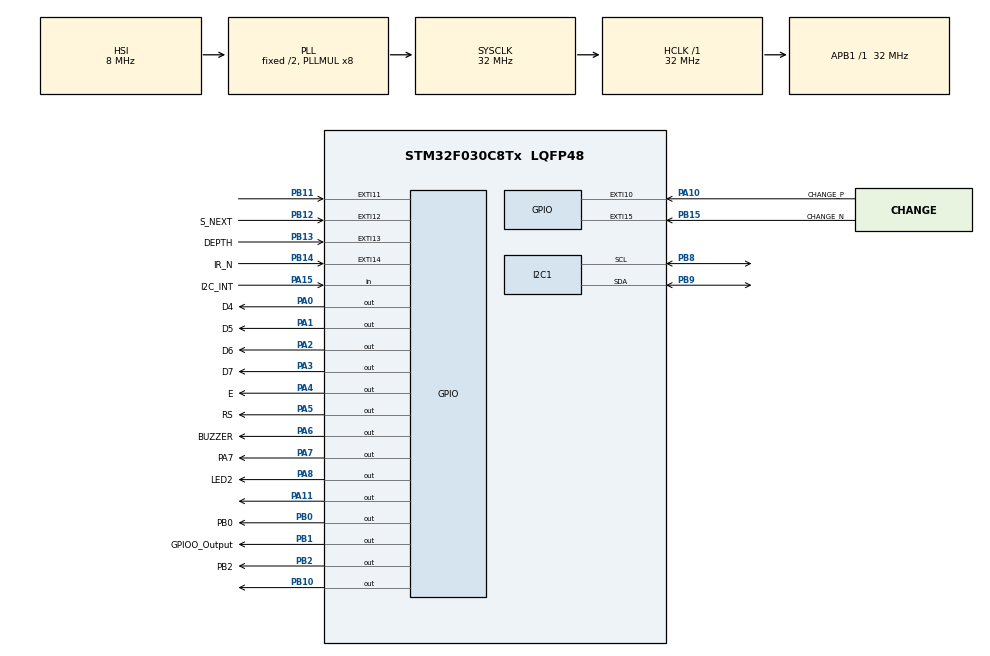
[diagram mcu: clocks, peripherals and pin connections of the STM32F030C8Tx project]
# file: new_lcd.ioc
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Mcu.Family=STM32F0
Mcu.Name=STM32F030C8Tx
Mcu.Package=LQFP48
PA0.GPIO_Label=D4
PA0.Signal=GPIO_Output
PA1.GPIO_Label=D5
PA1.Signal=GPIO_Output
PA10.GPIO_Label=CHANGE_P
PA10.Signal=GPXTI10
PA11.Signal=GPIO_Output
PA12.Signal=USART1_DE
PA13.Mode=Serial_Wire
PA13.Signal=SYS_SWDIO
PA14.Mode=Serial_Wire
PA14.Signal=SYS_SWCLK
PA15.GPIO_Label=I2C_INT
PA15.Signal=GPIO_Input
PA2.GPIO_Label=D6
PA2.Signal=GPIO_Output
PA3.GPIO_Label=D7
PA3.Signal=GPIO_Output
PA4.GPIO_Label=E
PA4.Signal=GPIO_Output
PA5.GPIO_Label=RS
PA5.Signal=GPIO_Output
PA6.GPIO_Label=BUZZER
PA6.Signal=GPIO_Output
PA7.GPIO_Label=PA7
PA7.Signal=GPIO_Output
PA8.GPIO_Label=LED2
PA8.Signal=GPIO_Output
PB0.GPIO_Label=PB0
PB0.Signal=GPIO_Output
PB1.GPIO_Label=GPIOO_Output
PB1.Signal=GPIO_Output
PB10.Signal=GPIO_Output
PB11.Signal=GPXTI11
PB12.GPIO_Label=S_NEXT
PB12.Signal=GPXTI12
PB13.GPIO_Label=DEPTH
PB13.Signal=GPXTI13
PB14.GPIO_Label=IR_N
PB14.Signal=GPXTI14
PB15.GPIO_Label=CHANGE_N
PB15.Signal=GPXTI15
PB2.GPIO_Label=PB2
PB2.Signal=GPIO_Output
PB6.Signal=USART1_TX
PB7.Signal=USART1_RX
PB8.Mode=I2C
PB8.Signal=I2C1_SCL
PB9.Mode=I2C
PB9.Signal=I2C1_SDA
PF0-OSC_IN.Mode=HSE-External-Oscillator
PF0-OSC_IN.Signal=RCC_OSC_IN
PF1-OSC_OUT.Mode=HSE-External-Oscillator
PF1-OSC_OUT.Signal=RCC_OSC_OUT
ProjectManager.HeapSize=0x200
ProjectManager.StackSize=0x400
ProjectManager.TargetToolchain=STM32CubeIDE
RCC.AHBFreq_Value=32000000
RCC.APB1Freq_Value=32000000
RCC.APB1TimFreq_Value=32000000
RCC.HCLKFreq_Value=32000000
RCC.PLLMUL=RCC_PLL_MUL8
RCC.SYSCLKFreq_VALUE=32000000
RCC.SYSCLKSource=RCC_SYSCLKSOURCE_PLLCLK
VP_TIM6_VS_ClockSourceINT.Mode=Enable_Timer
board=custom

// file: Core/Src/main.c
/* USER CODE BEGIN Header */
/**
  ******************************************************************************
  * @file           : main.c
  * @brief          : Main program body
  ******************************************************************************
  * @attention
  *
  * Copyright (c) 2023 STMicroelectronics.
  * All rights reserved.
  *
  * This software is licensed under terms that can be found in the LICENSE file
  * in the root directory of this software component.
  * If no LICENSE file comes with this software, it is provided AS-IS.
  *
  ******************************************************************************
  */
/* USER CODE END Header */
#include "main.h"

/* USER CODE BEGIN PTD */
//PIN_HIGH(D4_PORT, D4_PIN);
/* USER CODE END PTD */

I2C_HandleTypeDef hi2c1;

TIM_HandleTypeDef htim6;

void SystemClock_Config(void);
static void MX_GPIO_Init(void);
static void MX_I2C1_Init(void);
static void MX_TIM6_Init(void);

int main(void)
{

  /* MCU Configuration--------------------------------------------------------*/

  /* Reset of all peripherals, Initializes the Flash interface and the Systick. */
  HAL_Init();

  /* Configure the system clock */
  SystemClock_Config();

  /* Initialize all configured peripherals */
  MX_GPIO_Init();
  MX_I2C1_Init();
  MX_TIM6_Init();
  /* USER CODE BEGIN 2 */
#define BUTTON_STATE HAL_GPIO_ReadPin(GPIOB, GPIO_PIN_13)
#define LED_HIGH HAL_GPIO_WritePin(GPIOB, GPIO_PIN_11, GPIO_PIN_RESET)
#define LED_LOW HAL_GPIO_WritePin(GPIOB, GPIO_PIN_11, GPIO_PIN_SET)
  /* USER CODE END 2 */

  /* Infinite loop */
  while (1)
  {
//	    HAL_GPIO_WritePin(GPIOA, GPIO_PIN_13, 0);
//	  	HAL_Delay(1000);
//	  	HAL_GPIO_WritePin(GPIOA, GPIO_PIN_13, 1);
//	  	HAL_Delay(1000);
//		HAL_GPIO_WritePin(GPIOA, GPIO_PIN_13, 1);
//		  	HAL_Delay(1000);
    /* USER CODE BEGIN 3 */
	  if(BUTTON_STATE == 1)
	        {
	            LED_HIGH;
	        }
	      else
	        {
	            LED_LOW;
	        }
//		  	HAL_GPIO_TogglePin(GPIOA,pg2);
//		  		  	HAL_Delay(1000);
//			HAL_GPIO_TogglePin(GPIOA, GPIO_PIN_11);
//				  		  	HAL_Delay(1000);
//		  			HAL_GPIO_WritePin(GPIOA, GPIO_PIN_led1, 0);
//		  			  	HAL_Delay(1000);
  }
  /* USER CODE END 3 */
}

void SystemClock_Config(void)
{
  RCC_OscInitTypeDef RCC_OscInitStruct = {0};
  RCC_ClkInitTypeDef RCC_ClkInitStruct = {0};
  RCC_PeriphCLKInitTypeDef PeriphClkInit = {0};

  /** Initializes the RCC Oscillators according to the specified parameters
  * in the RCC_OscInitTypeDef structure.
  */
  RCC_OscInitStruct.OscillatorType = RCC_OSCILLATORTYPE_HSI;
  RCC_OscInitStruct.HSIState = RCC_HSI_ON;
  RCC_OscInitStruct.HSICalibrationValue = RCC_HSICALIBRATION_DEFAULT;
  RCC_OscInitStruct.PLL.PLLState = RCC_PLL_ON;
  RCC_OscInitStruct.PLL.PLLSource = RCC_PLLSOURCE_HSI;
  RCC_OscInitStruct.PLL.PLLMUL = RCC_PLL_MUL8;
  RCC_OscInitStruct.PLL.PREDIV = RCC_PREDIV_DIV1;
  if (HAL_RCC_OscConfig(&RCC_OscInitStruct) != HAL_OK)
  {
    Error_Handler();
  }

  /** Initializes the CPU, AHB and APB buses clocks
  */
  RCC_ClkInitStruct.ClockType = RCC_CLOCKTYPE_HCLK|RCC_CLOCKTYPE_SYSCLK
                              |RCC_CLOCKTYPE_PCLK1;
  RCC_ClkInitStruct.SYSCLKSource = RCC_SYSCLKSOURCE_PLLCLK;
  RCC_ClkInitStruct.AHBCLKDivider = RCC_SYSCLK_DIV1;
  RCC_ClkInitStruct.APB1CLKDivider = RCC_HCLK_DIV1;

  if (HAL_RCC_ClockConfig(&RCC_ClkInitStruct, FLASH_LATENCY_1) != HAL_OK)
  {
    Error_Handler();
  }
  PeriphClkInit.PeriphClockSelection = RCC_PERIPHCLK_I2C1;
  PeriphClkInit.I2c1ClockSelection = RCC_I2C1CLKSOURCE_HSI;
  if (HAL_RCCEx_PeriphCLKConfig(&PeriphClkInit) != HAL_OK)
  {
    Error_Handler();
  }
}

static void MX_I2C1_Init(void)
{

  hi2c1.Instance = I2C1;
  hi2c1.Init.Timing = 0x2000090E;
  hi2c1.Init.OwnAddress1 = 0;
  hi2c1.Init.AddressingMode = I2C_ADDRESSINGMODE_7BIT;
  hi2c1.Init.DualAddressMode = I2C_DUALADDRESS_DISABLE;
  hi2c1.Init.OwnAddress2 = 0;
  hi2c1.Init.OwnAddress2Masks = I2C_OA2_NOMASK;
  hi2c1.Init.GeneralCallMode = I2C_GENERALCALL_DISABLE;
  hi2c1.Init.NoStretchMode = I2C_NOSTRETCH_DISABLE;
  if (HAL_I2C_Init(&hi2c1) != HAL_OK)
  {
    Error_Handler();
  }

  /** Configure Analogue filter
  */
  if (HAL_I2CEx_ConfigAnalogFilter(&hi2c1, I2C_ANALOGFILTER_ENABLE) != HAL_OK)
  {
    Error_Handler();
  }

  /** Configure Digital filter
  */
  if (HAL_I2CEx_ConfigDigitalFilter(&hi2c1, 0) != HAL_OK)
  {
    Error_Handler();
  }

}

static void MX_TIM6_Init(void)
{

  htim6.Instance = TIM6;
  htim6.Init.Prescaler = 0;
  htim6.Init.CounterMode = TIM_COUNTERMODE_UP;
  htim6.Init.Period = 65535;
  htim6.Init.AutoReloadPreload = TIM_AUTORELOAD_PRELOAD_DISABLE;
  if (HAL_TIM_Base_Init(&htim6) != HAL_OK)
  {
    Error_Handler();
  }

}

static void MX_GPIO_Init(void)
{
  GPIO_InitTypeDef GPIO_InitStruct = {0};

  /* GPIO Ports Clock Enable */
  __HAL_RCC_GPIOF_CLK_ENABLE();
  __HAL_RCC_GPIOA_CLK_ENABLE();
  __HAL_RCC_GPIOB_CLK_ENABLE();

  /*Configure GPIO pin Output Level */
  HAL_GPIO_WritePin(GPIOA, D4_Pin|D5_Pin|D6_Pin|D7_Pin
                          |E_Pin|RS_Pin|BUZZER_Pin|PA7_Pin
                          |LED2_Pin|GPIO_PIN_11, GPIO_PIN_RESET);

  /*Configure GPIO pin Output Level */
  HAL_GPIO_WritePin(GPIOB, PB0_Pin|GPIOO_Output_Pin|PB2_Pin|GPIO_PIN_10, GPIO_PIN_RESET);

  /*Configure GPIO pins : D4_Pin D5_Pin D6_Pin D7_Pin
                           E_Pin RS_Pin BUZZER_Pin PA7_Pin
                           LED2_Pin PA11 */
  GPIO_InitStruct.Pin = D4_Pin|D5_Pin|D6_Pin|D7_Pin
                          |E_Pin|RS_Pin|BUZZER_Pin|PA7_Pin
                          |LED2_Pin|GPIO_PIN_11;
  GPIO_InitStruct.Mode = GPIO_MODE_OUTPUT_PP;
  GPIO_InitStruct.Pull = GPIO_NOPULL;
  GPIO_InitStruct.Speed = GPIO_SPEED_FREQ_LOW;
  HAL_GPIO_Init(GPIOA, &GPIO_InitStruct);

  /*Configure GPIO pins : PB0_Pin GPIOO_Output_Pin PB2_Pin PB10 */
  GPIO_InitStruct.Pin = PB0_Pin|GPIOO_Output_Pin|PB2_Pin|GPIO_PIN_10;
  GPIO_InitStruct.Mode = GPIO_MODE_OUTPUT_PP;
  GPIO_InitStruct.Pull = GPIO_NOPULL;
  GPIO_InitStruct.Speed = GPIO_SPEED_FREQ_LOW;
  HAL_GPIO_Init(GPIOB, &GPIO_InitStruct);

  /*Configure GPIO pins : PB11 S_NEXT_Pin DEPTH_Pin IR_N_Pin
                           CHANGE_N_Pin */
  GPIO_InitStruct.Pin = GPIO_PIN_11|S_NEXT_Pin|DEPTH_Pin|IR_N_Pin
                          |CHANGE_N_Pin;
  GPIO_InitStruct.Mode = GPIO_MODE_IT_RISING;
  GPIO_InitStruct.Pull = GPIO_NOPULL;
  HAL_GPIO_Init(GPIOB, &GPIO_InitStruct);

  /*Configure GPIO pin : CHANGE_P_Pin */
  GPIO_InitStruct.Pin = CHANGE_P_Pin;
  GPIO_InitStruct.Mode = GPIO_MODE_IT_RISING;
  GPIO_InitStruct.Pull = GPIO_NOPULL;
  HAL_GPIO_Init(CHANGE_P_GPIO_Port, &GPIO_InitStruct);

  /*Configure GPIO pin : PA12 */
  GPIO_InitStruct.Pin = GPIO_PIN_12;
  GPIO_InitStruct.Mode = GPIO_MODE_AF_PP;
  GPIO_InitStruct.Pull = GPIO_NOPULL;
  GPIO_InitStruct.Speed = GPIO_SPEED_FREQ_HIGH;
  GPIO_InitStruct.Alternate = GPIO_AF1_USART1;
  HAL_GPIO_Init(GPIOA, &GPIO_InitStruct);

  /*Configure GPIO pin : I2C_INT_Pin */
  GPIO_InitStruct.Pin = I2C_INT_Pin;
  GPIO_InitStruct.Mode = GPIO_MODE_INPUT;
  GPIO_InitStruct.Pull = GPIO_NOPULL;
  HAL_GPIO_Init(I2C_INT_GPIO_Port, &GPIO_InitStruct);

  /*Configure GPIO pins : PB6 PB7 */
  GPIO_InitStruct.Pin = GPIO_PIN_6|GPIO_PIN_7;
  GPIO_InitStruct.Mode = GPIO_MODE_AF_PP;
  GPIO_InitStruct.Pull = GPIO_NOPULL;
  GPIO_InitStruct.Speed = GPIO_SPEED_FREQ_HIGH;
  GPIO_InitStruct.Alternate = GPIO_AF0_USART1;
  HAL_GPIO_Init(GPIOB, &GPIO_InitStruct);

}

void Error_Handler(void)
{
  __disable_irq();
  while (1)
  {
  }
}
